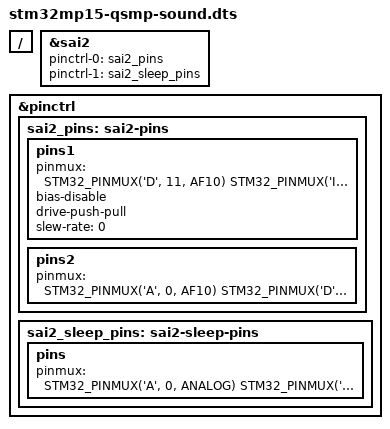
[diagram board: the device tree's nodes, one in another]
// SPDX-License-Identifier: (GPL-2.0 OR BSD-3-Clause)
/*
 * Copyright (C) 2022 Lothar Waßmann <LW@KARO-electronics.de>
 */

/dts-v1/;

/plugin/;

#include <dt-bindings/clock/stm32mp1-clks.h>
#include <dt-bindings/gpio/gpio.h>
#include <dt-bindings/interrupt-controller/arm-gic.h>
#include <dt-bindings/pinctrl/stm32-pinfunc.h>
#include "overlays/stm32mp15-karo-sound.dtsi"

/ {
	#address-cells = <1>;
	#size-cells = <0>;

	fragment@0 {
		reg = <0>;
		target = <&sai2>;

		__overlay__ {
			pinctrl-names = "default", "sleep";
			pinctrl-0 = <&sai2_pins>;
			pinctrl-1 = <&sai2_sleep_pins>;
		};

	};

	fragment@1 {
		reg = <1>;
		target = <&pinctrl>;

		__overlay__ {
			sai2_pins: sai2-pins {
				pins1 {
					pinmux = <
						STM32_PINMUX('D', 11, AF10)	/* TXD */
						STM32_PINMUX('I', 7, AF10)	/* FS */
					>;
					bias-disable;
					drive-push-pull;
					slew-rate = <0>;
				};

				pins2 {
					pinmux = <
						STM32_PINMUX('A', 0, AF10)	/* RXD */
						STM32_PINMUX('D', 13, AF10)	/* SCK */
					>;
				};
			};

			sai2_sleep_pins: sai2-sleep-pins {
				pins {
					pinmux = <
						STM32_PINMUX('A', 0, ANALOG)	/* RXD */
						STM32_PINMUX('D', 11, ANALOG)	/* TXD */
						STM32_PINMUX('D', 13, ANALOG)	/* SCK */
						STM32_PINMUX('I', 7, ANALOG)	/* FS */
					>;
				};
			};
		};
	};
};
